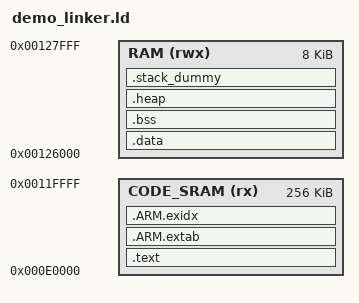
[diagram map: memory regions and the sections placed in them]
/*****************************************************************************
* © 2017 Microchip Technology Inc. and its subsidiaries.
* You may use this software and any derivatives exclusively with
* Microchip products.
* THIS SOFTWARE IS SUPPLIED BY MICROCHIP "AS IS".
* NO WARRANTIES, WHETHER EXPRESS, IMPLIED OR STATUTORY, APPLY TO THIS SOFTWARE,
* INCLUDING ANY IMPLIED WARRANTIES OF NON-INFRINGEMENT, MERCHANTABILITY,
* AND FITNESS FOR A PARTICULAR PURPOSE, OR ITS INTERACTION WITH MICROCHIP
* PRODUCTS, COMBINATION WITH ANY OTHER PRODUCTS, OR USE IN ANY APPLICATION.
* IN NO EVENT WILL MICROCHIP BE LIABLE FOR ANY INDIRECT, SPECIAL, PUNITIVE,
* INCIDENTAL OR CONSEQUENTIAL LOSS, DAMAGE, COST OR EXPENSE OF ANY KIND
* WHATSOEVER RELATED TO THE SOFTWARE, HOWEVER CAUSED, EVEN IF MICROCHIP HAS
* BEEN ADVISED OF THE POSSIBILITY OR THE DAMAGES ARE FORESEEABLE.
* TO THE FULLEST EXTENT ALLOWED BY LAW, MICROCHIP'S TOTAL LIABILITY ON ALL
* CLAIMS IN ANY WAY RELATED TO THIS SOFTWARE WILL NOT EXCEED THE AMOUNT OF
* FEES, IF ANY, THAT YOU HAVE PAID DIRECTLY TO MICROCHIP FOR THIS SOFTWARE.
* MICROCHIP PROVIDES THIS SOFTWARE CONDITIONALLY UPON YOUR ACCEPTANCE
* OF THESE TERMS.
*****************************************************************************/
/* Linker script to configure memory regions. 
 * Need modifying for a specific board. 
 *   ROM.ORIGIN: starting address of flash
 *   ROM.LENGTH: length of flash
 *   RAM.ORIGIN: starting address of RAM bank 0
 *   RAM.LENGTH: length of RAM bank 0
 */
MEMORY
{
  CODE_SRAM (rx)      : ORIGIN = 0x000E0000, LENGTH = 256K
  RAM (rwx)           : ORIGIN = 0x00126000, LENGTH = 0x2000  /* 8K */
}

__ram_end = ORIGIN(RAM) + LENGTH(RAM) ;

/* Linker script to place sections and symbol values. Should be used together
 * with other linker script that defines memory regions ROM and RAM.
 * It references following symbols, which must be defined in code:
 *   Reset_Handler : Entry of reset handler
 * 
 * It defines following symbols, which code can use without definition:
 *   __exidx_start
 *   __exidx_end
 *   __copy_table_start__
 *   __copy_table_end__
 *   __zero_table_start__
 *   __zero_table_end__
 *   __etext
 *   __data_start__
 *   __preinit_array_start
 *   __preinit_array_end
 *   __init_array_start
 *   __init_array_end
 *   __fini_array_start
 *   __fini_array_end
 *   __data_end__
 *   __bss_start__
 *   __bss_end__
 *   __end__
 *   end
 *   __HeapLimit
 *   __StackLimit
 *   __StackTop
 *   __stack
 */
ENTRY(Reset_Handler)

SECTIONS
{
    .text :
    {
        KEEP(*(.isr_vector))
        KEEP(*(.reset*))

        KEEP(*(.after_vectors))

        *(.text*)

        KEEP(*(.init))
        KEEP(*(.fini))

        /* .ctors */
        *crtbegin.o(.ctors)
        *crtbegin?.o(.ctors)
        *(EXCLUDE_FILE(*crtend?.o *crtend.o) .ctors)
        *(SORT(.ctors.*))
        *(.ctors)

        /* .dtors */
        *crtbegin.o(.dtors)
        *crtbegin?.o(.dtors)
        *(EXCLUDE_FILE(*crtend?.o *crtend.o) .dtors)
        *(SORT(.dtors.*))
        *(.dtors)

        . = ALIGN(4);
        *(.rodata*)
        
        . = ALIGN(4);
        *(vtable)
        
        . = ALIGN(4);
        /* preinit data */
        PROVIDE_HIDDEN (__preinit_array_start = .);
        KEEP(*(.preinit_array))
        PROVIDE_HIDDEN (__preinit_array_end = .);

        . = ALIGN(4);
        /* init data */
        PROVIDE_HIDDEN (__init_array_start = .);
        KEEP(*(SORT(.init_array.*)))
        KEEP(*(.init_array))
        PROVIDE_HIDDEN (__init_array_end = .);

        . = ALIGN(4);
        /* finit data */
        PROVIDE_HIDDEN (__fini_array_start = .);
        KEEP(*(SORT(.fini_array.*)))
        KEEP(*(.fini_array))
        PROVIDE_HIDDEN (__fini_array_end = .);

        KEEP(*(.jcr*))
        . = ALIGN(4);

        KEEP(*(.eh_frame*))
    } > CODE_SRAM =0xffffffff

    .ARM.extab : 
    {
        *(.ARM.extab* .gnu.linkonce.armextab.*)
    } > CODE_SRAM

    __exidx_start = .;
    .ARM.exidx :
    {
        *(.ARM.exidx* .gnu.linkonce.armexidx.*)
    } > CODE_SRAM
    __exidx_end = .;

    /* To copy multiple ROM to RAM sections,
     * uncomment .copy.table section and,
     * define __STARTUP_COPY_MULTIPLE in startup_ARMCMx.S */
    /*
    .copy.table :
    {
        . = ALIGN(4);
        __copy_table_start__ = .;
        LONG (__etext)
        LONG (__data_start__)
        LONG (__data_end__ - __data_start__)
        LONG (__etext2)
        LONG (__data2_start__)
        LONG (__data2_end__ - __data2_start__)
        __copy_table_end__ = .;
    } > CODE_SRAM
    */

    /* To clear multiple BSS sections,
     * uncomment .zero.table section and,
     * define __STARTUP_CLEAR_BSS_MULTIPLE in startup_ARMCMx.S */
    /*
    .zero.table :
    {
        . = ALIGN(4);
        __zero_table_start__ = .;
        LONG (__bss_start__)
        LONG (__bss_end__ - __bss_start__)
        LONG (__bss2_start__)
        LONG (__bss2_end__ - __bss2_start__)
        __zero_table_end__ = .;
    } > CODE_SRAM
    */

    __etext = .;
    _sidata = __etext;          /* used by _startup.c */

    .data : AT (__etext)
    {
        _sdata = . ;            /* used by _startup.c */
        __data_start__ = .;
        /* *(vtable) move to ROM code space */
        *(.data*)

        . = ALIGN(4);
        /* All data end */
        _edata = .;             /* used by _startup.c */
        __data_end__ = .;

    } > RAM

    .bss :
    {
        . = ALIGN(4);
        __bss_start__ = .;
        *(.bss*)
        *(COMMON)
        . = ALIGN(4);
        __bss_end__ = .;
    } > RAM

    .heap (COPY):
    {
        __end__ = .;
        _Heap = .;
        PROVIDE(end = .);
        *(.heap*)
        __HeapLimit = .;
        _Heap_End = .;
    } > RAM

    /* .stack_dummy section doesn't contains any symbols. It is only
     * used for linker to calculate size of stack sections, and assign
     * values to stack symbols later */
    .stack_dummy (COPY):
    {
        *(.stack*)
    } > RAM

    /* Set stack top to end of RAM, and stack limit move down by
     * size of stack_dummy section */
    /* __ram_end */
    /* __StackTop = ORIGIN(RAM) + LENGTH(RAM); */
    __StackTop = __ram_end ;
    __StackLimit = __StackTop - SIZEOF(.stack_dummy);
    PROVIDE(__stack = __StackTop);
    
    /* Check if data + heap + stack exceeds RAM limit */
    ASSERT(__StackLimit >= __HeapLimit, "region RAM overflowed with stack")

}
